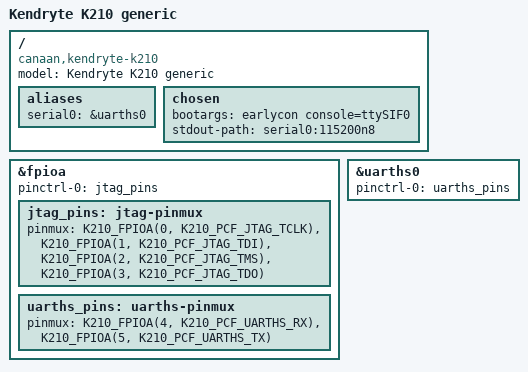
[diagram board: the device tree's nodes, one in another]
// SPDX-License-Identifier: GPL-2.0+
/*
 * Copyright (C) 2019-20 Sean Anderson <seanga2@gmail.com>
 * Copyright (C) 2020 Western Digital Corporation or its affiliates.
 */

/dts-v1/;

#include "k210.dtsi"

#include <dt-bindings/gpio/gpio.h>
#include <dt-bindings/input/input.h>

/ {
	model = "Kendryte K210 generic";
	compatible = "canaan,kendryte-k210";

	aliases {
		serial0 = &uarths0;
	};

	chosen {
		bootargs = "earlycon console=ttySIF0";
		stdout-path = "serial0:115200n8";
	};
};

&fpioa {
	pinctrl-0 = <&jtag_pins>;
	pinctrl-names = "default";

	jtag_pins: jtag-pinmux {
		pinmux = <K210_FPIOA(0, K210_PCF_JTAG_TCLK)>,
			 <K210_FPIOA(1, K210_PCF_JTAG_TDI)>,
			 <K210_FPIOA(2, K210_PCF_JTAG_TMS)>,
			 <K210_FPIOA(3, K210_PCF_JTAG_TDO)>;
	};

	uarths_pins: uarths-pinmux {
		pinmux = <K210_FPIOA(4, K210_PCF_UARTHS_RX)>,
			 <K210_FPIOA(5, K210_PCF_UARTHS_TX)>;
	};
};

&uarths0 {
	pinctrl-0 = <&uarths_pins>;
	pinctrl-names = "default";
	status = "okay";
};
